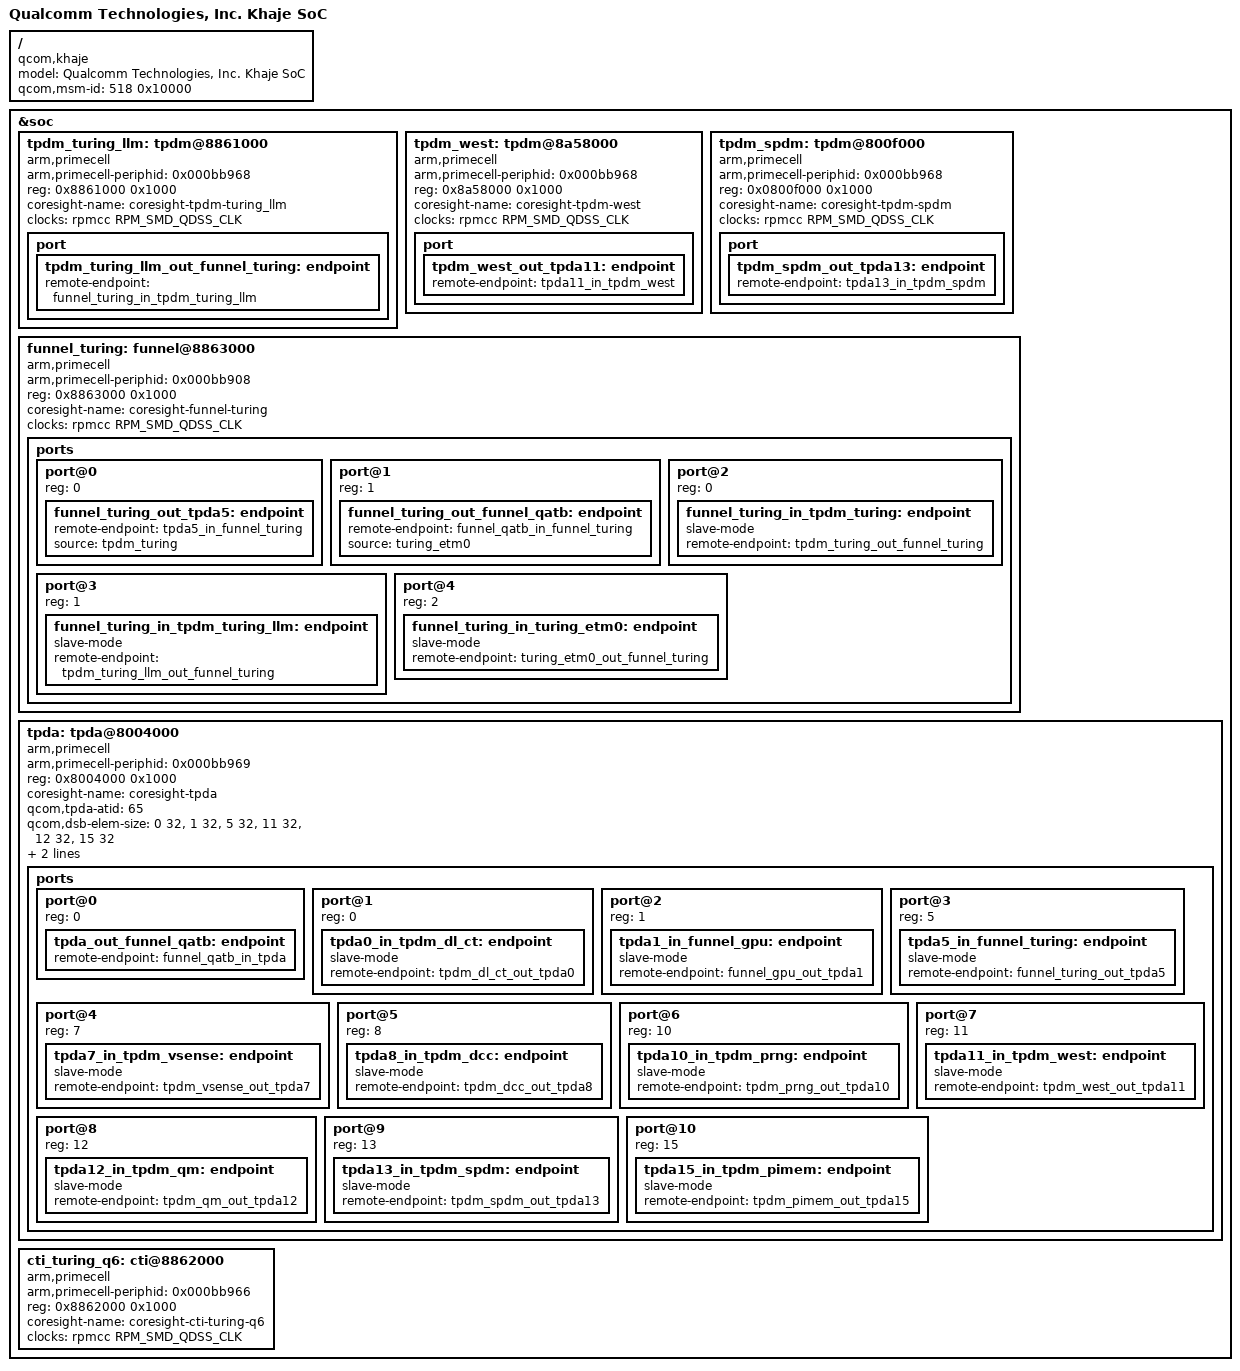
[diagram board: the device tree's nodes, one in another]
#include "bengal.dtsi"

/ {
	model = "Qualcomm Technologies, Inc. Khaje SoC";
	compatible = "qcom,khaje";
	qcom,msm-id = <518 0x10000>;
};

&soc {
	tpdm_turing_llm: tpdm@8861000 {
		compatible = "arm,primecell";
		arm,primecell-periphid = <0x000bb968>;
		reg = <0x8861000 0x1000>;
		reg-names = "tpdm-base";

		coresight-name = "coresight-tpdm-turing_llm";

		clocks = <&rpmcc RPM_SMD_QDSS_CLK>;
		clock-names = "apb_pclk";
		port {
			tpdm_turing_llm_out_funnel_turing: endpoint {
				remote-endpoint =
				<&funnel_turing_in_tpdm_turing_llm>;
			};
		};
	};

	/delete-node/ tpdm@8a58000;
	tpdm_west: tpdm@8a58000 {
		compatible = "arm,primecell";
		arm,primecell-periphid = <0x000bb968>;
		reg = <0x8a58000 0x1000>;
		reg-names = "tpdm-base";

		coresight-name = "coresight-tpdm-west";

		clocks = <&rpmcc RPM_SMD_QDSS_CLK>;
		clock-names = "apb_pclk";
		port {
			tpdm_west_out_tpda11: endpoint {
				remote-endpoint =
				<&tpda11_in_tpdm_west>;
			};
		};
	};

	tpdm_spdm: tpdm@800f000 {
		compatible = "arm,primecell";
		arm,primecell-periphid = <0x000bb968>;
		reg = <0x0800f000 0x1000>;
		reg-names = "tpdm-base";

		coresight-name = "coresight-tpdm-spdm";

		clocks = <&rpmcc RPM_SMD_QDSS_CLK>;
		clock-names = "apb_pclk";
		port {
			tpdm_spdm_out_tpda13: endpoint {
				remote-endpoint =
				<&tpda13_in_tpdm_spdm>;
			};
		};
	};

	/delete-node/ funnel@8861000;
	funnel_turing: funnel@8863000 {
		compatible = "arm,primecell";
		arm,primecell-periphid = <0x000bb908>;
		reg = <0x8863000 0x1000>;
		reg-names = "funnel-base";

		coresight-name = "coresight-funnel-turing";

		clocks = <&rpmcc RPM_SMD_QDSS_CLK>;
		clock-names = "apb_pclk";
		ports {
			#address-cells = <1>;
			#size-cells = <0>;
			port@0 {
				reg = <0>;
				funnel_turing_out_tpda5: endpoint {
					remote-endpoint =
					<&tpda5_in_funnel_turing>;
					source = <&tpdm_turing>;
				};
			};

			port@1 {
				reg = <1>;
				funnel_turing_out_funnel_qatb: endpoint {
					remote-endpoint =
					<&funnel_qatb_in_funnel_turing>;
					source = <&turing_etm0>;
				};
			};

			port@2 {
				reg = <0>;
				funnel_turing_in_tpdm_turing: endpoint {
					slave-mode;
					remote-endpoint =
					<&tpdm_turing_out_funnel_turing>;
				};
			};

			port@3 {
				reg = <1>;
				funnel_turing_in_tpdm_turing_llm: endpoint {
					slave-mode;
					remote-endpoint =
					<&tpdm_turing_llm_out_funnel_turing>;
				};
			};

			port@4 {
				reg = <2>;
				funnel_turing_in_turing_etm0: endpoint {
					slave-mode;
					remote-endpoint =
					<&turing_etm0_out_funnel_turing>;
				};
			};
		};
	};

	/delete-node/ tpda@8004000;
	tpda: tpda@8004000 {
		compatible = "arm,primecell";
		arm,primecell-periphid = <0x000bb969>;
		reg = <0x8004000 0x1000>;
		reg-names = "tpda-base";

		coresight-name = "coresight-tpda";

		qcom,tpda-atid = <65>;
		qcom,dsb-elem-size = <0 32>,
						<1 32>,
						<5 32>,
						<11 32>,
						<12 32>,
						<15 32>;
		qcom,cmb-elem-size = <7 32>,
						<8 32>,
						<10 32>,
						<15 64>;

		clocks = <&rpmcc RPM_SMD_QDSS_CLK>;
		clock-names = "apb_pclk";

		ports {
			#address-cells = <1>;
			#size-cells = <0>;
			port@0 {
				reg = <0>;
				tpda_out_funnel_qatb: endpoint {
					remote-endpoint =
					<&funnel_qatb_in_tpda>;
				};
			};

			port@1 {
				reg = <0>;
				tpda0_in_tpdm_dl_ct: endpoint {
					slave-mode;
					remote-endpoint =
					<&tpdm_dl_ct_out_tpda0>;
				};
			};

			port@2 {
				reg = <1>;
				tpda1_in_funnel_gpu: endpoint {
					slave-mode;
					remote-endpoint =
					<&funnel_gpu_out_tpda1>;
				};
			};

			port@3 {
				reg = <5>;
				tpda5_in_funnel_turing: endpoint {
					slave-mode;
					remote-endpoint =
					<&funnel_turing_out_tpda5>;
				};
			};

			port@4 {
				reg = <7>;
				tpda7_in_tpdm_vsense: endpoint {
					slave-mode;
					remote-endpoint =
					<&tpdm_vsense_out_tpda7>;
				};
			};

			port@5 {
				reg = <8>;
				tpda8_in_tpdm_dcc: endpoint {
					slave-mode;
					remote-endpoint =
					<&tpdm_dcc_out_tpda8>;
				};
			};

			port@6 {
				reg = <10>;
				tpda10_in_tpdm_prng: endpoint {
					slave-mode;
					remote-endpoint =
					<&tpdm_prng_out_tpda10>;
				};
			};

			port@7 {
				reg = <11>;
				tpda11_in_tpdm_west: endpoint {
					slave-mode;
					remote-endpoint =
					<&tpdm_west_out_tpda11>;
				};
			};

			port@8 {
				reg = <12>;
				tpda12_in_tpdm_qm: endpoint {
					slave-mode;
					remote-endpoint =
					<&tpdm_qm_out_tpda12>;
				};
			};

			port@9 {
				reg = <13>;
				tpda13_in_tpdm_spdm: endpoint {
					slave-mode;
					remote-endpoint =
					<&tpdm_spdm_out_tpda13>;
				};
			};

			port@10 {
				reg = <15>;
				tpda15_in_tpdm_pimem: endpoint {
					slave-mode;
					remote-endpoint =
					<&tpdm_pimem_out_tpda15>;
				};
			};

		};
	};

	/delete-node/ cti@8867000;
	cti_turing_q6: cti@8862000 {
		compatible = "arm,primecell";
		arm,primecell-periphid = <0x000bb966>;
		reg = <0x8862000 0x1000>;
		reg-names = "cti-base";

		coresight-name = "coresight-cti-turing-q6";

		clocks = <&rpmcc RPM_SMD_QDSS_CLK>;
		clock-names = "apb_pclk";
	};
};
